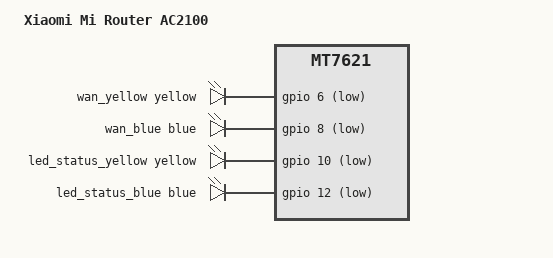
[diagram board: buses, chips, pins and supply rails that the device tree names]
// SPDX-License-Identifier: GPL-2.0-or-later OR MIT

#include <dt-bindings/leds/common.h>

#include "mt7621_xiaomi_router-ac2100.dtsi"

/ {
	compatible = "xiaomi,mi-router-ac2100", "mediatek,mt7621-soc";
	model = "Xiaomi Mi Router AC2100";

	aliases {
		led-boot = &led_status_yellow;
		led-failsafe = &led_status_yellow;
		led-running = &led_status_blue;
		led-upgrade = &led_status_blue;
		label-mac-device = &gmac0;
	};

	leds {
		compatible = "gpio-leds";

		wan_yellow {
			function = LED_FUNCTION_WAN;
			color = <LED_COLOR_ID_YELLOW>;
			gpios = <&gpio 6 GPIO_ACTIVE_LOW>;
		};

		wan_blue {
			function = LED_FUNCTION_WAN;
			color = <LED_COLOR_ID_BLUE>;
			gpios = <&gpio 8 GPIO_ACTIVE_LOW>;
		};

		led_status_yellow: status_yellow {
			function = LED_FUNCTION_STATUS;
			color = <LED_COLOR_ID_YELLOW>;
			gpios = <&gpio 10 GPIO_ACTIVE_LOW>;
		};

		led_status_blue: status_blue {
			function = LED_FUNCTION_STATUS;
			color = <LED_COLOR_ID_BLUE>;
			gpios = <&gpio 12 GPIO_ACTIVE_LOW>;
		};
	};
};
